# apollo4b register map
Vendor: Ambiq Micro; Series: Apollo; File version: 1.0
CPU: CM4 r1p0, little endian, MPU, FPU, I-cache, D-cache, VTOR, ITCM, DTCM, 3 interrupt priority bits, 0 interrupts
Registers are 32-bit, read-write, reset 0x0 unless marked. A register's access mark holds for its fields unless they carry their own. Offsets are from the block's base; [hi:lo] are bit positions; {n}, {i} and the like mark numbered series; 'fields as' and 'values as' point back to an identical list.

## GPIO (part 3 of 4) — General Purpose IO
Base 0x40010000
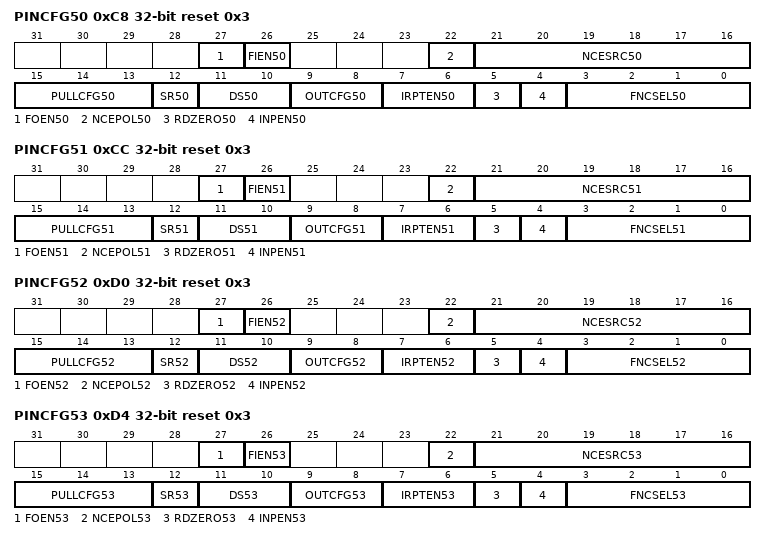
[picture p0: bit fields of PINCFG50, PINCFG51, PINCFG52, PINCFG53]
0xC8 PINCFG50 reset 0x3 — Controls the operation of GPIO pin 50.
  [27] FOEN50 — Force output enable active regardless of function selected. Otherwise the selected function will enable the output only when needed
  [26] FIEN50 — Force input enable active regardless of function selected. Otherwise the selected function will enable the input only when needed
  [22] NCEPOL50 — Polarity select for NCE for GPIO 50
    0=LOW (Polarity is active low); 1=HIGH (Polarity is active high)
  [21:16] NCESRC50 — IOMSTR/MSPI N Chip Select 50, DISP control signals DE, CSX, and CS. Polarity is determined by CE_POLARITY field
    {v}=IOM0CE{v} (IOM 0 NCE {v} module) (v=0..3); {v}=IOM1CE{v-4} (IOM 1 NCE {v-4} module) (v=4..7); {v}=IOM2CE{v-8} (IOM 2 NCE {v-8} module) (v=8..11); {v}=IOM3CE{v-12} (IOM 3 NCE {v-12} module) (v=12..15); {v}=IOM4CE{v-16} (IOM 4 NCE {v-16} module) (v=16..19); {v}=IOM5CE{v-20} (IOM 5 NCE {v-20} module) (v=20..23); {v}=IOM6CE{v-24} (IOM 6 NCE {v-24} module) (v=24..27); {v}=IOM7CE{v-28} (IOM 7 NCE {v-28} module) (v=28..31); 32=MSPI0CEN0 (MSPI 0 NCE 0 module); 33=MSPI0CEN1 (MSPI 0 NCE 1 module); 34=MSPI1CEN0 (MSPI 1 NCE 0 module); 35=MSPI1CEN1 (MSPI 1 NCE 1 module); 36=MSPI2CEN0 (MSPI 2 NCE 0 module); 37=MSPI2CEN1 (MSPI 2 NCE 1 module); 38=DC_DPI_DE (DC DPI DE module); 39=DISP_CONT_CSX (DISP CONT CSX module); 40=DC_SPI_CS_N (DC SPI CS_N module); 41=DC_QSPI_CS_N (DC QSPI CS_N module); 42=DC_RESX (DC module RESX)
  [15:13] PULLCFG50 — Pullup/Pulldown configuration for GPIO 50
    0=DIS (No pullup or pulldown selected); 1=PD50K (50K Pulldown selected); 2=PU15K (1.5K Pullup selected); 3=PU6K (6K Pullup selected); 4=PU12K (12K Pullup selected); 5=PU24K (24K Pullup selected); 6=PU50K (50K Pullup selected); 7=PU100K (100K Pullup selected)
  [12] SR50 — Configure the slew rate
  [11:10] DS50 — Drive strength selection for GPIO 50
    0=0P1X (0.1x output driver selected); 1=0P5X (0.5x output driver selected)
  [9:8] OUTCFG50 — Pin IO mode selection for GPIO pin 50
    0=DIS (Output Disabled); 1=PUSHPULL (Output configured in push pull mode. Will drive 0 and 1 values on pin.); 2=OD (Output configured in open drain mode. Will only drive pin low, tristate otherwise.); 3=TS (Output configured in Tristate-able push pull mode. Will drive 0, 1 of HiZ on pin.)
  [7:6] IRPTEN50 — Interrupt enable for GPIO 50
    0=DIS (Interrupts are disabled for this GPIO); 1=INTFALL (Interrupts are enabled for falling edge transition on this GPIO); 2=INTRISE (Interrupts are enabled for rising edge transitions on this GPIO); 3=INTANY (Interrupts are enabled for any edge transition on this GPIO)
  [5] RDZERO50 — Return 0 for read data on GPIO 50
  [4] INPEN50 — Input enable for GPIO 50
  [3:0] FNCSEL50 — Function select for GPIO pin 50
    0=PDM0_CLK (PDMx Clock output (I2C Master/Slave D)); 1=TRIG0 (ADC trigger input); 2=SWTRACECLK (Serial Wire Debug Trace Clock); 3=GPIO (General purpose I/O); 4=UART2RTS (UART Request to Send (RTS) (UART 2)); 5=UART3RTS (UART Request to Send (RTS) (UART 3)); 6=CT50 (Timer/Counter input or output; Selection of direction is done via CTIMER register settings.); 7=NCE50 (IOMSTR/MSPI N Chip Select. Polarity is determined by CE_POLARITY field); 8=OBSBUS2 (Observation bus bit 2); 9=DISP_TE (Display TE input); 11=FPIO (Fast PIO)
0xCC PINCFG51 reset 0x3 — Controls the operation of GPIO pin 51.
  [27] FOEN51 — Force output enable active regardless of function selected. Otherwise the selected function will enable the output only when needed
  [26] FIEN51 — Force input enable active regardless of function selected. Otherwise the selected function will enable the input only when needed
  [22] NCEPOL51 — Polarity select for NCE for GPIO 51
    values as PINCFG50.NCEPOL50
  [21:16] NCESRC51 — IOMSTR/MSPI N Chip Select 51, DISP control signals DE, CSX, and CS. Polarity is determined by CE_POLARITY field
    values as PINCFG50.NCESRC50
  [15:13] PULLCFG51 — Pullup/Pulldown configuration for GPIO 51
    values as PINCFG50.PULLCFG50
  [12] SR51 — Configure the slew rate
  [11:10] DS51 — Drive strength selection for GPIO 51
    0=0P1X (0.1x output driver selected); 1=0P5X (0.5x output driver selected); 2=0P75X (0.75x output driver selected); 3=1P0X (1.0x output driver selected)
  [9:8] OUTCFG51 — Pin IO mode selection for GPIO pin 51
    values as PINCFG50.OUTCFG50
  [7:6] IRPTEN51 — Interrupt enable for GPIO 51
    values as PINCFG50.IRPTEN50
  [5] RDZERO51 — Return 0 for read data on GPIO 51
  [4] INPEN51 — Input enable for GPIO 51
  [3:0] FNCSEL51 — Function select for GPIO pin 51
    0=PDM0_DATA (PDMx audio data input to chip (I2C Master/Slave D)); 1=TRIG1 (ADC trigger input); 2=SWTRACE0 (Serial Wire Debug Trace Output 0); 3=GPIO (General purpose I/O); 4=UART0CTS (UART Clear to Send (CTS) (UART 0)); 5=UART1CTS (UART Clear to Send (CTS) (UART 1)); 6=CT51 (Timer/Counter input or output; Selection of direction is done via CTIMER register settings.); 7=NCE51 (IOMSTR/MSPI N Chip Select. Polarity is determined by CE_POLARITY field); 8=OBSBUS3 (Observation bus bit 3); 11=FPIO (Fast PIO)
0xD0 PINCFG52 reset 0x3 — Controls the operation of GPIO pin 52.
  [27] FOEN52 — Force output enable active regardless of function selected. Otherwise the selected function will enable the output only when needed
  [26] FIEN52 — Force input enable active regardless of function selected. Otherwise the selected function will enable the input only when needed
  [22] NCEPOL52 — Polarity select for NCE for GPIO 52
    values as PINCFG50.NCEPOL50
  [21:16] NCESRC52 — IOMSTR/MSPI N Chip Select 52, DISP control signals DE, CSX, and CS. Polarity is determined by CE_POLARITY field
    values as PINCFG50.NCESRC50
  [15:13] PULLCFG52 — Pullup/Pulldown configuration for GPIO 52
    values as PINCFG50.PULLCFG50
  [12] SR52 — Configure the slew rate
  [11:10] DS52 — Drive strength selection for GPIO 52
    values as PINCFG51.DS51
  [9:8] OUTCFG52 — Pin IO mode selection for GPIO pin 52
    values as PINCFG50.OUTCFG50
  [7:6] IRPTEN52 — Interrupt enable for GPIO 52
    values as PINCFG50.IRPTEN50
  [5] RDZERO52 — Return 0 for read data on GPIO 52
  [4] INPEN52 — Input enable for GPIO 52
  [3:0] FNCSEL52 — Function select for GPIO pin 52
    0=PDM1_CLK (PDMx Clock output (I2C Master/Slave D)); 1=TRIG2 (ADC trigger input); 2=SWTRACE1 (Serial Wire Debug Trace Output 1); 3=GPIO (General purpose I/O); 4=UART2CTS (UART Clear to Send (CTS) (UART 2)); 5=UART3CTS (UART Clear to Send (CTS) (UART 3)); 6=CT52 (Timer/Counter input or output; Selection of direction is done via CTIMER register settings.); 7=NCE52 (IOMSTR/MSPI N Chip Select. Polarity is determined by CE_POLARITY field); 8=OBSBUS4 (Observation bus bit 4); 9=VCMPO (Output of the voltage comparator signal); 11=FPIO (Fast PIO)
0xD4 PINCFG53 reset 0x3 — Controls the operation of GPIO pin 53.
  [27] FOEN53 — Force output enable active regardless of function selected. Otherwise the selected function will enable the output only when needed
  [26] FIEN53 — Force input enable active regardless of function selected. Otherwise the selected function will enable the input only when needed
  [22] NCEPOL53 — Polarity select for NCE for GPIO 53
    values as PINCFG50.NCEPOL50
  [21:16] NCESRC53 — IOMSTR/MSPI N Chip Select 53, DISP control signals DE, CSX, and CS. Polarity is determined by CE_POLARITY field
    values as PINCFG50.NCESRC50
  [15:13] PULLCFG53 — Pullup/Pulldown configuration for GPIO 53
    values as PINCFG50.PULLCFG50
  [12] SR53 — Configure the slew rate
  [11:10] DS53 — Drive strength selection for GPIO 53
    values as PINCFG51.DS51
  [9:8] OUTCFG53 — Pin IO mode selection for GPIO pin 53
    values as PINCFG50.OUTCFG50
  [7:6] IRPTEN53 — Interrupt enable for GPIO 53
    values as PINCFG50.IRPTEN50
  [5] RDZERO53 — Return 0 for read data on GPIO 53
  [4] INPEN53 — Input enable for GPIO 53
  [3:0] FNCSEL53 — Function select for GPIO pin 53
    0=PDM1_DATA (PDMx audio data input to chip (I2C Master/Slave D)); 1=TRIG3 (ADC trigger input); 2=SWTRACE2 (Serial Wire Debug Trace Output 2); 3=GPIO (General purpose I/O); 4=UART0TX (UART transmit output (UART 0)); 5=UART1TX (UART transmit output (UART 1)); 6=CT53 (Timer/Counter input or output; Selection of direction is done via CTIMER register settings.); 7=NCE53 (IOMSTR/MSPI N Chip Select. Polarity is determined by CE_POLARITY field); 8=OBSBUS5 (Observation bus bit 5); 11=FPIO (Fast PIO)
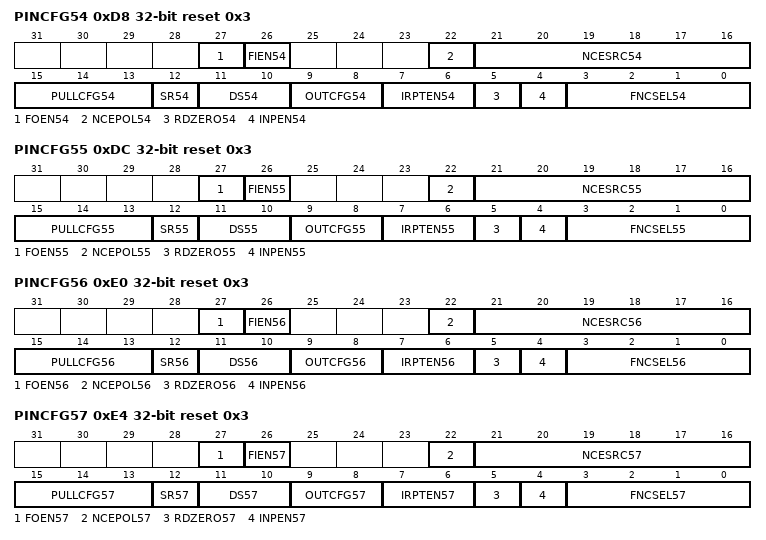
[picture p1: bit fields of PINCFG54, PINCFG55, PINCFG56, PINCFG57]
0xD8 PINCFG54 reset 0x3 — Controls the operation of GPIO pin 54.
  [27] FOEN54 — Force output enable active regardless of function selected. Otherwise the selected function will enable the output only when needed
  [26] FIEN54 — Force input enable active regardless of function selected. Otherwise the selected function will enable the input only when needed
  [22] NCEPOL54 — Polarity select for NCE for GPIO 54
    values as PINCFG50.NCEPOL50
  [21:16] NCESRC54 — IOMSTR/MSPI N Chip Select 54, DISP control signals DE, CSX, and CS. Polarity is determined by CE_POLARITY field
    values as PINCFG50.NCESRC50
  [15:13] PULLCFG54 — Pullup/Pulldown configuration for GPIO 54
    values as PINCFG50.PULLCFG50
  [12] SR54 — Configure the slew rate
  [11:10] DS54 — Drive strength selection for GPIO 54
    values as PINCFG51.DS51
  [9:8] OUTCFG54 — Pin IO mode selection for GPIO pin 54
    values as PINCFG50.OUTCFG50
  [7:6] IRPTEN54 — Interrupt enable for GPIO 54
    values as PINCFG50.IRPTEN50
  [5] RDZERO54 — Return 0 for read data on GPIO 54
  [4] INPEN54 — Input enable for GPIO 54
  [3:0] FNCSEL54 — Function select for GPIO pin 54
    0=PDM2_CLK (PDMx Clock output (I2C Master/Slave D)); 1=TRIG0 (ADC trigger input); 2=SWTRACE3 (Serial Wire Debug Trace Output 3); 3=GPIO (General purpose I/O); 4=UART2TX (UART transmit output (UART 2)); 5=UART3TX (UART transmit output (UART 3)); 6=CT54 (Timer/Counter input or output; Selection of direction is done via CTIMER register settings.); 7=NCE54 (IOMSTR/MSPI N Chip Select. Polarity is determined by CE_POLARITY field); 8=OBSBUS6 (Observation bus bit 6); 11=FPIO (Fast PIO)
0xDC PINCFG55 reset 0x3 — Controls the operation of GPIO pin 55.
  [27] FOEN55 — Force output enable active regardless of function selected. Otherwise the selected function will enable the output only when needed
  [26] FIEN55 — Force input enable active regardless of function selected. Otherwise the selected function will enable the input only when needed
  [22] NCEPOL55 — Polarity select for NCE for GPIO 55
    values as PINCFG50.NCEPOL50
  [21:16] NCESRC55 — IOMSTR/MSPI N Chip Select 55, DISP control signals DE, CSX, and CS. Polarity is determined by CE_POLARITY field
    values as PINCFG50.NCESRC50
  [15:13] PULLCFG55 — Pullup/Pulldown configuration for GPIO 55
    values as PINCFG50.PULLCFG50
  [12] SR55 — Configure the slew rate
  [11:10] DS55 — Drive strength selection for GPIO 55
    values as PINCFG51.DS51
  [9:8] OUTCFG55 — Pin IO mode selection for GPIO pin 55
    values as PINCFG50.OUTCFG50
  [7:6] IRPTEN55 — Interrupt enable for GPIO 55
    values as PINCFG50.IRPTEN50
  [5] RDZERO55 — Return 0 for read data on GPIO 55
  [4] INPEN55 — Input enable for GPIO 55
  [3:0] FNCSEL55 — Function select for GPIO pin 55
    0=PDM2_DATA (PDMx audio data input to chip (I2C Master/Slave D)); 1=TRIG1 (ADC trigger input); 2=SWTRACECTL (Serial Wire Debug Trace Control); 3=GPIO (General purpose I/O); 4=UART0RX (UART receive input (UART 0)); 5=UART1RX (UART receive input (UART 1)); 6=CT55 (Timer/Counter input or output; Selection of direction is done via CTIMER register settings.); 7=NCE55 (IOMSTR/MSPI N Chip Select. Polarity is determined by CE_POLARITY field); 8=OBSBUS7 (Observation bus bit 7); 11=FPIO (Fast PIO)
0xE0 PINCFG56 reset 0x3 — Controls the operation of GPIO pin 56.
  [27] FOEN56 — Force output enable active regardless of function selected. Otherwise the selected function will enable the output only when needed
  [26] FIEN56 — Force input enable active regardless of function selected. Otherwise the selected function will enable the input only when needed
  [22] NCEPOL56 — Polarity select for NCE for GPIO 56
    values as PINCFG50.NCEPOL50
  [21:16] NCESRC56 — IOMSTR/MSPI N Chip Select 56, DISP control signals DE, CSX, and CS. Polarity is determined by CE_POLARITY field
    values as PINCFG50.NCESRC50
  [15:13] PULLCFG56 — Pullup/Pulldown configuration for GPIO 56
    values as PINCFG50.PULLCFG50
  [12] SR56 — Configure the slew rate
  [11:10] DS56 — Drive strength selection for GPIO 56
    values as PINCFG51.DS51
  [9:8] OUTCFG56 — Pin IO mode selection for GPIO pin 56
    values as PINCFG50.OUTCFG50
  [7:6] IRPTEN56 — Interrupt enable for GPIO 56
    values as PINCFG50.IRPTEN50
  [5] RDZERO56 — Return 0 for read data on GPIO 56
  [4] INPEN56 — Input enable for GPIO 56
  [3:0] FNCSEL56 — Function select for GPIO pin 56
    0=PDM3_CLK (PDMx Clock output (I2C Master/Slave D)); 1=TRIG2 (ADC trigger input); 2=SWO (Serial Wire Output); 3=GPIO (General purpose I/O); 4=UART2RX (UART receive input (UART 2)); 5=UART3RX (UART receive input (UART 3)); 6=CT56 (Timer/Counter input or output; Selection of direction is done via CTIMER register settings.); 7=NCE56 (IOMSTR/MSPI N Chip Select. Polarity is determined by CE_POLARITY field); 8=OBSBUS8 (Observation bus bit 8); 11=FPIO (Fast PIO)
0xE4 PINCFG57 reset 0x3 — Controls the operation of GPIO pin 57.
  [27] FOEN57 — Force output enable active regardless of function selected. Otherwise the selected function will enable the output only when needed
  [26] FIEN57 — Force input enable active regardless of function selected. Otherwise the selected function will enable the input only when needed
  [22] NCEPOL57 — Polarity select for NCE for GPIO 57
    values as PINCFG50.NCEPOL50
  [21:16] NCESRC57 — IOMSTR/MSPI N Chip Select 57, DISP control signals DE, CSX, and CS. Polarity is determined by CE_POLARITY field
    values as PINCFG50.NCESRC50
  [15:13] PULLCFG57 — Pullup/Pulldown configuration for GPIO 57
    values as PINCFG50.PULLCFG50
  [12] SR57 — Configure the slew rate
  [11:10] DS57 — Drive strength selection for GPIO 57
    values as PINCFG51.DS51
  [9:8] OUTCFG57 — Pin IO mode selection for GPIO pin 57
    values as PINCFG50.OUTCFG50
  [7:6] IRPTEN57 — Interrupt enable for GPIO 57
    values as PINCFG50.IRPTEN50
  [5] RDZERO57 — Return 0 for read data on GPIO 57
  [4] INPEN57 — Input enable for GPIO 57
  [3:0] FNCSEL57 — Function select for GPIO pin 57
    0=PDM3_DATA (PDMx audio data input to chip (I2C Master/Slave D)); 1=TRIG3 (ADC trigger input); 2=SWO (Serial Wire Output); 3=GPIO (General purpose I/O); 4=UART0RTS (UART Request to Send (RTS) (UART 0)); 5=UART1RTS (UART Request to Send (RTS) (UART 1)); 6=CT57 (Timer/Counter input or output; Selection of direction is done via CTIMER register settings.); 7=NCE57 (IOMSTR/MSPI N Chip Select. Polarity is determined by CE_POLARITY field); 8=OBSBUS9 (Observation bus bit 9); 9=VCMPO (Output of the voltage comparator signal); 11=FPIO (Fast PIO)
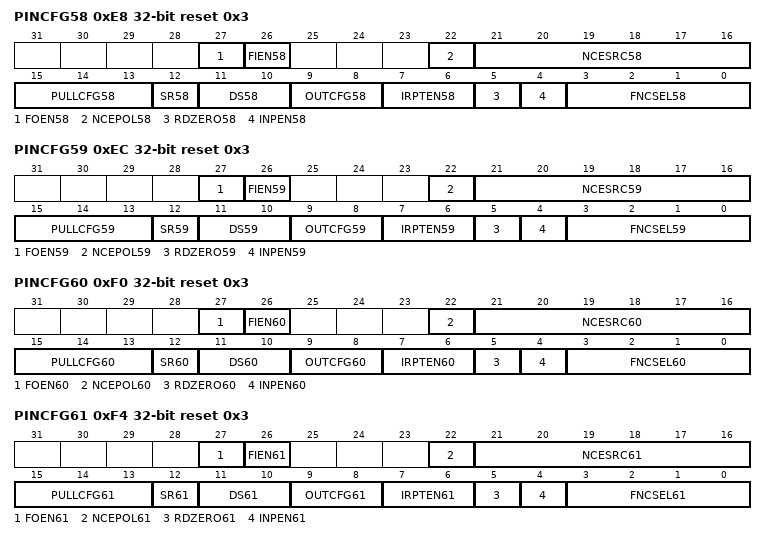
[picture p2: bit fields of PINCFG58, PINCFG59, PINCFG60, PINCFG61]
0xE8 PINCFG58 reset 0x3 — Controls the operation of GPIO pin 58.
  [27] FOEN58 — Force output enable active regardless of function selected. Otherwise the selected function will enable the output only when needed
  [26] FIEN58 — Force input enable active regardless of function selected. Otherwise the selected function will enable the input only when needed
  [22] NCEPOL58 — Polarity select for NCE for GPIO 58
    values as PINCFG50.NCEPOL50
  [21:16] NCESRC58 — IOMSTR/MSPI N Chip Select 58, DISP control signals DE, CSX, and CS. Polarity is determined by CE_POLARITY field
    values as PINCFG50.NCESRC50
  [15:13] PULLCFG58 — Pullup/Pulldown configuration for GPIO 58
    values as PINCFG50.PULLCFG50
  [12] SR58 — Configure the slew rate
  [11:10] DS58 — Drive strength selection for GPIO 58
    values as PINCFG50.DS50
  [9:8] OUTCFG58 — Pin IO mode selection for GPIO pin 58
    values as PINCFG50.OUTCFG50
  [7:6] IRPTEN58 — Interrupt enable for GPIO 58
    values as PINCFG50.IRPTEN50
  [5] RDZERO58 — Return 0 for read data on GPIO 58
  [4] INPEN58 — Input enable for GPIO 58
  [3:0] FNCSEL58 — Function select for GPIO pin 58
    3=GPIO (General purpose I/O); 4=UART0RTS (UART Request to Send (RTS) (UART 0)); 5=UART3RTS (UART Request to Send (RTS) (UART 3)); 6=CT58 (Timer/Counter input or output; Selection of direction is done via CTIMER register settings.); 7=NCE58 (IOMSTR/MSPI N Chip Select. Polarity is determined by CE_POLARITY field); 8=OBSBUS10 (Observation bus bit 10); 11=FPIO (Fast PIO)
0xEC PINCFG59 reset 0x3 — Controls the operation of GPIO pin 59.
  [27] FOEN59 — Force output enable active regardless of function selected. Otherwise the selected function will enable the output only when needed
  [26] FIEN59 — Force input enable active regardless of function selected. Otherwise the selected function will enable the input only when needed
  [22] NCEPOL59 — Polarity select for NCE for GPIO 59
    values as PINCFG50.NCEPOL50
  [21:16] NCESRC59 — IOMSTR/MSPI N Chip Select 59, DISP control signals DE, CSX, and CS. Polarity is determined by CE_POLARITY field
    values as PINCFG50.NCESRC50
  [15:13] PULLCFG59 — Pullup/Pulldown configuration for GPIO 59
    values as PINCFG50.PULLCFG50
  [12] SR59 — Configure the slew rate
  [11:10] DS59 — Drive strength selection for GPIO 59
    values as PINCFG50.DS50
  [9:8] OUTCFG59 — Pin IO mode selection for GPIO pin 59
    values as PINCFG50.OUTCFG50
  [7:6] IRPTEN59 — Interrupt enable for GPIO 59
    values as PINCFG50.IRPTEN50
  [5] RDZERO59 — Return 0 for read data on GPIO 59
  [4] INPEN59 — Input enable for GPIO 59
  [3:0] FNCSEL59 — Function select for GPIO pin 59
    1=TRIG0 (ADC trigger input); 3=GPIO (General purpose I/O); 4=UART0CTS (UART Clear to Send (CTS) (UART 0)); 5=UART1CTS (UART Clear to Send (CTS) (UART 1)); 6=CT59 (Timer/Counter input or output; Selection of direction is done via CTIMER register settings.); 7=NCE59 (IOMSTR/MSPI N Chip Select. Polarity is determined by CE_POLARITY field); 8=OBSBUS11 (Observation bus bit 11); 11=FPIO (Fast PIO)
0xF0 PINCFG60 reset 0x3 — Controls the operation of GPIO pin 60.
  [27] FOEN60 — Force output enable active regardless of function selected. Otherwise the selected function will enable the output only when needed
  [26] FIEN60 — Force input enable active regardless of function selected. Otherwise the selected function will enable the input only when needed
  [22] NCEPOL60 — Polarity select for NCE for GPIO 60
    values as PINCFG50.NCEPOL50
  [21:16] NCESRC60 — IOMSTR/MSPI N Chip Select 60, DISP control signals DE, CSX, and CS. Polarity is determined by CE_POLARITY field
    values as PINCFG50.NCESRC50
  [15:13] PULLCFG60 — Pullup/Pulldown configuration for GPIO 60
    values as PINCFG50.PULLCFG50
  [12] SR60 — Configure the slew rate
  [11:10] DS60 — Drive strength selection for GPIO 60
    values as PINCFG50.DS50
  [9:8] OUTCFG60 — Pin IO mode selection for GPIO pin 60
    values as PINCFG50.OUTCFG50
  [7:6] IRPTEN60 — Interrupt enable for GPIO 60
    values as PINCFG50.IRPTEN50
  [5] RDZERO60 — Return 0 for read data on GPIO 60
  [4] INPEN60 — Input enable for GPIO 60
  [3:0] FNCSEL60 — Function select for GPIO pin 60
    1=TRIG1 (ADC trigger input); 3=GPIO (General purpose I/O); 4=UART0TX (UART transmit output (UART 0)); 5=UART3CTS (UART Clear to Send (CTS) (UART 3)); 6=CT60 (Timer/Counter input or output; Selection of direction is done via CTIMER register settings.); 7=NCE60 (IOMSTR/MSPI N Chip Select. Polarity is determined by CE_POLARITY field); 8=OBSBUS12 (Observation bus bit 12); 11=FPIO (Fast PIO)
0xF4 PINCFG61 reset 0x3 — Controls the operation of GPIO pin 61.
  [27] FOEN61 — Force output enable active regardless of function selected. Otherwise the selected function will enable the output only when needed
  [26] FIEN61 — Force input enable active regardless of function selected. Otherwise the selected function will enable the input only when needed
  [22] NCEPOL61 — Polarity select for NCE for GPIO 61
    values as PINCFG50.NCEPOL50
  [21:16] NCESRC61 — IOMSTR/MSPI N Chip Select 61, DISP control signals DE, CSX, and CS. Polarity is determined by CE_POLARITY field
    values as PINCFG50.NCESRC50
  [15:13] PULLCFG61 — Pullup/Pulldown configuration for GPIO 61
    values as PINCFG50.PULLCFG50
  [12] SR61 — Configure the slew rate
  [11:10] DS61 — Drive strength selection for GPIO 61
    values as PINCFG51.DS51
  [9:8] OUTCFG61 — Pin IO mode selection for GPIO pin 61
    values as PINCFG50.OUTCFG50
  [7:6] IRPTEN61 — Interrupt enable for GPIO 61
    values as PINCFG50.IRPTEN50
  [5] RDZERO61 — Return 0 for read data on GPIO 61
  [4] INPEN61 — Input enable for GPIO 61
  [3:0] FNCSEL61 — Function select for GPIO pin 61
    0=M6SCL (Serial I2C Master Clock output (IOM 6)); 1=M6SCK (Serial SPI Master Clock output (IOM 6)); 2=I2S1_CLK (Bidirectional I2S Bit clock. Operates in output mode in master mode and input mode for slave mode. (I2S Master/Slave 2)); 3=GPIO (General purpose I/O); 4=UART2TX (UART transmit output (UART 2)); 5=UART3TX (UART transmit output (UART 3)); 6=CT61 (Timer/Counter input or output; Selection of direction is done via CTIMER register settings.); 7=NCE61 (IOMSTR/MSPI N Chip Select. Polarity is determined by CE_POLARITY field); 8=OBSBUS13 (Observation bus bit 13); 11=FPIO (Fast PIO)
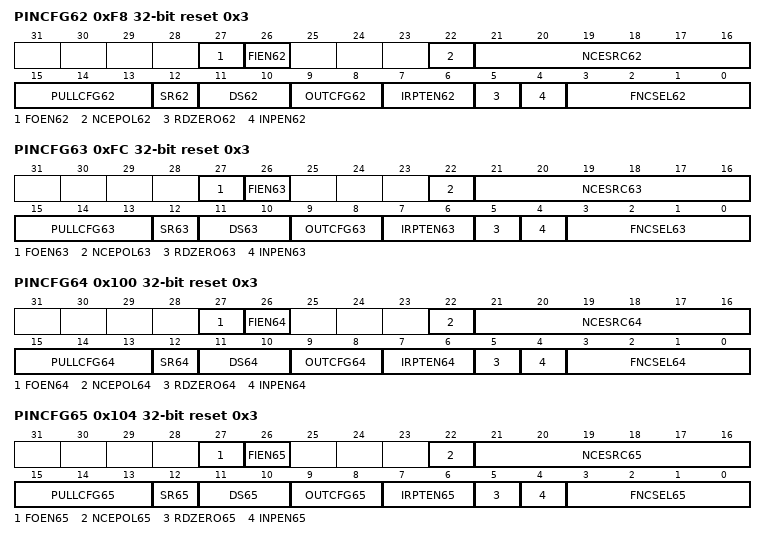
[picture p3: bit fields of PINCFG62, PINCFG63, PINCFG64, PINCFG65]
0xF8 PINCFG62 reset 0x3 — Controls the operation of GPIO pin 62.
  [27] FOEN62 — Force output enable active regardless of function selected. Otherwise the selected function will enable the output only when needed
  [26] FIEN62 — Force input enable active regardless of function selected. Otherwise the selected function will enable the input only when needed
  [22] NCEPOL62 — Polarity select for NCE for GPIO 62
    values as PINCFG50.NCEPOL50
  [21:16] NCESRC62 — IOMSTR/MSPI N Chip Select 62, DISP control signals DE, CSX, and CS. Polarity is determined by CE_POLARITY field
    values as PINCFG50.NCESRC50
  [15:13] PULLCFG62 — Pullup/Pulldown configuration for GPIO 62
    values as PINCFG50.PULLCFG50
  [12] SR62 — Configure the slew rate
  [11:10] DS62 — Drive strength selection for GPIO 62
    values as PINCFG51.DS51
  [9:8] OUTCFG62 — Pin IO mode selection for GPIO pin 62
    values as PINCFG50.OUTCFG50
  [7:6] IRPTEN62 — Interrupt enable for GPIO 62
    values as PINCFG50.IRPTEN50
  [5] RDZERO62 — Return 0 for read data on GPIO 62
  [4] INPEN62 — Input enable for GPIO 62
  [3:0] FNCSEL62 — Function select for GPIO pin 62
    0=M6SDAWIR3 (Serial I2C Master Data I/O (I2C Mode) Serial SPI Master Data I/O (SPI 3 wire mode) (IOM 6)); 1=M6MOSI (Serial SPI Master MOSI output (IOM 6)); 2=I2S1_DATA (Bidirectional I2S Data. Operates in output mode in master mode and input mode for slave mode. (I2S Master/Slave 2)); 3=GPIO (General purpose I/O); 4=UART0RX (UART receive input (UART 0)); 5=UART1RX (UART receive input (UART 1)); 6=CT62 (Timer/Counter input or output; Selection of direction is done via CTIMER register settings.); 7=NCE62 (IOMSTR/MSPI N Chip Select. Polarity is determined by CE_POLARITY field); 8=OBSBUS14 (Observation bus bit 14); 9=I2S1_SDOUT (I2S Data output (I2S Master/Slave 2)); 11=FPIO (Fast PIO)
0xFC PINCFG63 reset 0x3 — Controls the operation of GPIO pin 63.
  [27] FOEN63 — Force output enable active regardless of function selected. Otherwise the selected function will enable the output only when needed
  [26] FIEN63 — Force input enable active regardless of function selected. Otherwise the selected function will enable the input only when needed
  [22] NCEPOL63 — Polarity select for NCE for GPIO 63
    values as PINCFG50.NCEPOL50
  [21:16] NCESRC63 — IOMSTR/MSPI N Chip Select 63, DISP control signals DE, CSX, and CS. Polarity is determined by CE_POLARITY field
    values as PINCFG50.NCESRC50
  [15:13] PULLCFG63 — Pullup/Pulldown configuration for GPIO 63
    values as PINCFG50.PULLCFG50
  [12] SR63 — Configure the slew rate
  [11:10] DS63 — Drive strength selection for GPIO 63
    values as PINCFG51.DS51
  [9:8] OUTCFG63 — Pin IO mode selection for GPIO pin 63
    values as PINCFG50.OUTCFG50
  [7:6] IRPTEN63 — Interrupt enable for GPIO 63
    values as PINCFG50.IRPTEN50
  [5] RDZERO63 — Return 0 for read data on GPIO 63
  [4] INPEN63 — Input enable for GPIO 63
  [3:0] FNCSEL63 — Function select for GPIO pin 63
    0=M6MISO (Serial SPI MASTER MISO input (IOM 6)); 1=CLKOUT (Oscillator output clock); 2=I2S1_WS (Bidirectional I2S L/R clock. Operates in output mode in master mode and input mode for slave mode. (I2S Master/Slave 2)); 3=GPIO (General purpose I/O); 4=UART2RX (UART receive input (UART 2)); 5=UART3RX (UART receive input (UART 3)); 6=CT63 (Timer/Counter input or output; Selection of direction is done via CTIMER register settings.); 7=NCE63 (IOMSTR/MSPI N Chip Select. Polarity is determined by CE_POLARITY field); 8=OBSBUS15 (Observation bus bit 15); 9=DISP_TE (Display TE input); 11=FPIO (Fast PIO)
0x100 PINCFG64 reset 0x3 — Controls the operation of GPIO pin 64.
  [27] FOEN64 — Force output enable active regardless of function selected. Otherwise the selected function will enable the output only when needed
  [26] FIEN64 — Force input enable active regardless of function selected. Otherwise the selected function will enable the input only when needed
  [22] NCEPOL64 — Polarity select for NCE for GPIO 64
    values as PINCFG50.NCEPOL50
  [21:16] NCESRC64 — IOMSTR/MSPI N Chip Select 64, DISP control signals DE, CSX, and CS. Polarity is determined by CE_POLARITY field
    values as PINCFG50.NCESRC50
  [15:13] PULLCFG64 — Pullup/Pulldown configuration for GPIO 64
    values as PINCFG50.PULLCFG50
  [12] SR64 — Configure the slew rate
  [11:10] DS64 — Drive strength selection for GPIO 64
    values as PINCFG51.DS51
  [9:8] OUTCFG64 — Pin IO mode selection for GPIO pin 64
    values as PINCFG50.OUTCFG50
  [7:6] IRPTEN64 — Interrupt enable for GPIO 64
    values as PINCFG50.IRPTEN50
  [5] RDZERO64 — Return 0 for read data on GPIO 64
  [4] INPEN64 — Input enable for GPIO 64
  [3:0] FNCSEL64 — Function select for GPIO pin 64
    0=MSPI0_0 (MSPI Master 0 Interface Signal); 1=32KHzXT (32kHZ from analog); 2=SWO (Serial Wire Output); 3=GPIO (General purpose I/O); 4=UART0RTS (UART Request to Send (RTS) (UART 0)); 5=DISP_D0 (Display Data 0); 6=CT64 (Timer/Counter input or output; Selection of direction is done via CTIMER register settings.); 7=NCE64 (IOMSTR/MSPI N Chip Select. Polarity is determined by CE_POLARITY field); 8=OBSBUS0 (Observation bus bit 0); 9=I2S1_SDIN (I2S Data input (I2S Master/Slave 2)); 11=FPIO (Fast PIO)
0x104 PINCFG65 reset 0x3 — Controls the operation of GPIO pin 65.
  [27] FOEN65 — Force output enable active regardless of function selected. Otherwise the selected function will enable the output only when needed
  [26] FIEN65 — Force input enable active regardless of function selected. Otherwise the selected function will enable the input only when needed
  [22] NCEPOL65 — Polarity select for NCE for GPIO 65
    values as PINCFG50.NCEPOL50
  [21:16] NCESRC65 — IOMSTR/MSPI N Chip Select 65, DISP control signals DE, CSX, and CS. Polarity is determined by CE_POLARITY field
    values as PINCFG50.NCESRC50
  [15:13] PULLCFG65 — Pullup/Pulldown configuration for GPIO 65
    values as PINCFG50.PULLCFG50
  [12] SR65 — Configure the slew rate
  [11:10] DS65 — Drive strength selection for GPIO 65
    values as PINCFG51.DS51
  [9:8] OUTCFG65 — Pin IO mode selection for GPIO pin 65
    values as PINCFG50.OUTCFG50
  [7:6] IRPTEN65 — Interrupt enable for GPIO 65
    values as PINCFG50.IRPTEN50
  [5] RDZERO65 — Return 0 for read data on GPIO 65
  [4] INPEN65 — Input enable for GPIO 65
  [3:0] FNCSEL65 — Function select for GPIO pin 65
    0=MSPI0_1 (MSPI Master 0 Interface Signal); 1=32KHzXT (32kHZ from analog); 2=SWO (Serial Wire Output); 3=GPIO (General purpose I/O); 4=UART0CTS (UART Clear to Send (CTS) (UART 0)); 5=DISP_D1 (Display Data 1); 6=CT65 (Timer/Counter input or output; Selection of direction is done via CTIMER register settings.); 7=NCE65 (IOMSTR/MSPI N Chip Select. Polarity is determined by CE_POLARITY field); 8=OBSBUS1 (Observation bus bit 1); 11=FPIO (Fast PIO)
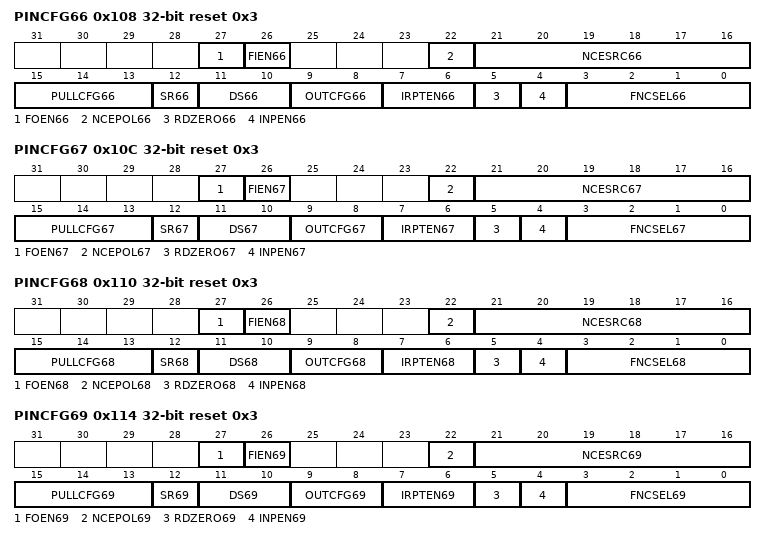
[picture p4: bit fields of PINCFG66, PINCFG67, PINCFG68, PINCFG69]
0x108 PINCFG66 reset 0x3 — Controls the operation of GPIO pin 66.
  [27] FOEN66 — Force output enable active regardless of function selected. Otherwise the selected function will enable the output only when needed
  [26] FIEN66 — Force input enable active regardless of function selected. Otherwise the selected function will enable the input only when needed
  [22] NCEPOL66 — Polarity select for NCE for GPIO 66
    values as PINCFG50.NCEPOL50
  [21:16] NCESRC66 — IOMSTR/MSPI N Chip Select 66, DISP control signals DE, CSX, and CS. Polarity is determined by CE_POLARITY field
    values as PINCFG50.NCESRC50
  [15:13] PULLCFG66 — Pullup/Pulldown configuration for GPIO 66
    values as PINCFG50.PULLCFG50
  [12] SR66 — Configure the slew rate
  [11:10] DS66 — Drive strength selection for GPIO 66
    values as PINCFG51.DS51
  [9:8] OUTCFG66 — Pin IO mode selection for GPIO pin 66
    values as PINCFG50.OUTCFG50
  [7:6] IRPTEN66 — Interrupt enable for GPIO 66
    values as PINCFG50.IRPTEN50
  [5] RDZERO66 — Return 0 for read data on GPIO 66
  [4] INPEN66 — Input enable for GPIO 66
  [3:0] FNCSEL66 — Function select for GPIO pin 66
    0=MSPI0_2 (MSPI Master 0 Interface Signal); 1=CLKOUT (Oscillator output clock); 2=SWO (Serial Wire Output); 3=GPIO (General purpose I/O); 4=UART0TX (UART transmit output (UART 0)); 5=DISP_D2 (Display Data 2); 6=CT66 (Timer/Counter input or output; Selection of direction is done via CTIMER register settings.); 7=NCE66 (IOMSTR/MSPI N Chip Select. Polarity is determined by CE_POLARITY field); 8=OBSBUS2 (Observation bus bit 2); 11=FPIO (Fast PIO)
0x10C PINCFG67 reset 0x3 — Controls the operation of GPIO pin 67.
  [27] FOEN67 — Force output enable active regardless of function selected. Otherwise the selected function will enable the output only when needed
  [26] FIEN67 — Force input enable active regardless of function selected. Otherwise the selected function will enable the input only when needed
  [22] NCEPOL67 — Polarity select for NCE for GPIO 67
    values as PINCFG50.NCEPOL50
  [21:16] NCESRC67 — IOMSTR/MSPI N Chip Select 67, DISP control signals DE, CSX, and CS. Polarity is determined by CE_POLARITY field
    values as PINCFG50.NCESRC50
  [15:13] PULLCFG67 — Pullup/Pulldown configuration for GPIO 67
    values as PINCFG50.PULLCFG50
  [12] SR67 — Configure the slew rate
  [11:10] DS67 — Drive strength selection for GPIO 67
    values as PINCFG51.DS51
  [9:8] OUTCFG67 — Pin IO mode selection for GPIO pin 67
    values as PINCFG50.OUTCFG50
  [7:6] IRPTEN67 — Interrupt enable for GPIO 67
    values as PINCFG50.IRPTEN50
  [5] RDZERO67 — Return 0 for read data on GPIO 67
  [4] INPEN67 — Input enable for GPIO 67
  [3:0] FNCSEL67 — Function select for GPIO pin 67
    0=MSPI0_3 (MSPI Master 0 Interface Signal); 1=CLKOUT (Oscillator output clock); 2=SWO (Serial Wire Output); 3=GPIO (General purpose I/O); 4=UART2TX (UART transmit output (UART 2)); 5=DISP_D3 (Display Data 3); 6=CT67 (Timer/Counter input or output; Selection of direction is done via CTIMER register settings.); 7=NCE67 (IOMSTR/MSPI N Chip Select. Polarity is determined by CE_POLARITY field); 8=OBSBUS3 (Observation bus bit 3); 11=FPIO (Fast PIO)
0x110 PINCFG68 reset 0x3 — Controls the operation of GPIO pin 68.
  [27] FOEN68 — Force output enable active regardless of function selected. Otherwise the selected function will enable the output only when needed
  [26] FIEN68 — Force input enable active regardless of function selected. Otherwise the selected function will enable the input only when needed
  [22] NCEPOL68 — Polarity select for NCE for GPIO 68
    values as PINCFG50.NCEPOL50
  [21:16] NCESRC68 — IOMSTR/MSPI N Chip Select 68, DISP control signals DE, CSX, and CS. Polarity is determined by CE_POLARITY field
    values as PINCFG50.NCESRC50
  [15:13] PULLCFG68 — Pullup/Pulldown configuration for GPIO 68
    values as PINCFG50.PULLCFG50
  [12] SR68 — Configure the slew rate
  [11:10] DS68 — Drive strength selection for GPIO 68
    values as PINCFG51.DS51
  [9:8] OUTCFG68 — Pin IO mode selection for GPIO pin 68
    values as PINCFG50.OUTCFG50
  [7:6] IRPTEN68 — Interrupt enable for GPIO 68
    values as PINCFG50.IRPTEN50
  [5] RDZERO68 — Return 0 for read data on GPIO 68
  [4] INPEN68 — Input enable for GPIO 68
  [3:0] FNCSEL68 — Function select for GPIO pin 68
    0=MSPI0_4 (MSPI Master 0 Interface Signal); 1=SWO (Serial Wire Output); 3=GPIO (General purpose I/O); 4=UART0RX (UART receive input (UART 0)); 5=DISP_D4 (Display Data 4); 6=CT68 (Timer/Counter input or output; Selection of direction is done via CTIMER register settings.); 7=NCE68 (IOMSTR/MSPI N Chip Select. Polarity is determined by CE_POLARITY field); 8=OBSBUS4 (Observation bus bit 4); 11=FPIO (Fast PIO)
0x114 PINCFG69 reset 0x3 — Controls the operation of GPIO pin 69.
  [27] FOEN69 — Force output enable active regardless of function selected. Otherwise the selected function will enable the output only when needed
  [26] FIEN69 — Force input enable active regardless of function selected. Otherwise the selected function will enable the input only when needed
  [22] NCEPOL69 — Polarity select for NCE for GPIO 69
    values as PINCFG50.NCEPOL50
  [21:16] NCESRC69 — IOMSTR/MSPI N Chip Select 69, DISP control signals DE, CSX, and CS. Polarity is determined by CE_POLARITY field
    values as PINCFG50.NCESRC50
  [15:13] PULLCFG69 — Pullup/Pulldown configuration for GPIO 69
    values as PINCFG50.PULLCFG50
  [12] SR69 — Configure the slew rate
  [11:10] DS69 — Drive strength selection for GPIO 69
    values as PINCFG51.DS51
  [9:8] OUTCFG69 — Pin IO mode selection for GPIO pin 69
    values as PINCFG50.OUTCFG50
  [7:6] IRPTEN69 — Interrupt enable for GPIO 69
    values as PINCFG50.IRPTEN50
  [5] RDZERO69 — Return 0 for read data on GPIO 69
  [4] INPEN69 — Input enable for GPIO 69
  [3:0] FNCSEL69 — Function select for GPIO pin 69
    0=MSPI0_5 (MSPI Master 0 Interface Signal); 1=32KHzXT (32kHZ from analog); 2=SWO (Serial Wire Output); 3=GPIO (General purpose I/O); 4=UART2RX (UART receive input (UART 2)); 5=DISP_D5 (Display Data 5); 6=CT69 (Timer/Counter input or output; Selection of direction is done via CTIMER register settings.); 7=NCE69 (IOMSTR/MSPI N Chip Select. Polarity is determined by CE_POLARITY field); 8=OBSBUS5 (Observation bus bit 5); 11=FPIO (Fast PIO)
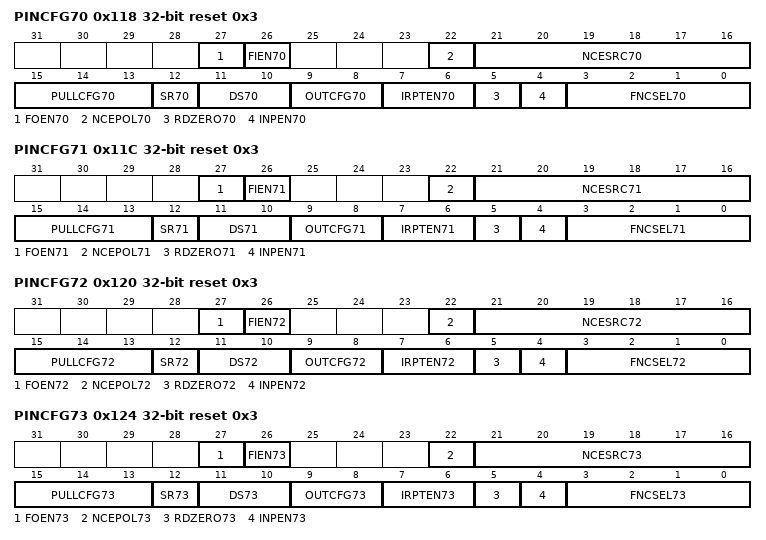
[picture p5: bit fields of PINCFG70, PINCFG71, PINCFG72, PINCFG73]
0x118 PINCFG70 reset 0x3 — Controls the operation of GPIO pin 70.
  [27] FOEN70 — Force output enable active regardless of function selected. Otherwise the selected function will enable the output only when needed
  [26] FIEN70 — Force input enable active regardless of function selected. Otherwise the selected function will enable the input only when needed
  [22] NCEPOL70 — Polarity select for NCE for GPIO 70
    values as PINCFG50.NCEPOL50
  [21:16] NCESRC70 — IOMSTR/MSPI N Chip Select 70, DISP control signals DE, CSX, and CS. Polarity is determined by CE_POLARITY field
    values as PINCFG50.NCESRC50
  [15:13] PULLCFG70 — Pullup/Pulldown configuration for GPIO 70
    values as PINCFG50.PULLCFG50
  [12] SR70 — Configure the slew rate
  [11:10] DS70 — Drive strength selection for GPIO 70
    values as PINCFG51.DS51
  [9:8] OUTCFG70 — Pin IO mode selection for GPIO pin 70
    values as PINCFG50.OUTCFG50
  [7:6] IRPTEN70 — Interrupt enable for GPIO 70
    values as PINCFG50.IRPTEN50
  [5] RDZERO70 — Return 0 for read data on GPIO 70
  [4] INPEN70 — Input enable for GPIO 70
  [3:0] FNCSEL70 — Function select for GPIO pin 70
    0=MSPI0_6 (MSPI Master 0 Interface Signal); 1=32KHzXT (32kHZ from analog); 2=SWTRACE0 (Serial Wire Debug Trace Output 0); 3=GPIO (General purpose I/O); 4=UART0RTS (UART Request to Send (RTS) (UART 0)); 5=DISP_D6 (Display Data 6); 6=CT70 (Timer/Counter input or output; Selection of direction is done via CTIMER register settings.); 7=NCE70 (IOMSTR/MSPI N Chip Select. Polarity is determined by CE_POLARITY field); 8=OBSBUS6 (Observation bus bit 6); 11=FPIO (Fast PIO)
0x11C PINCFG71 reset 0x3 — Controls the operation of GPIO pin 71.
  [27] FOEN71 — Force output enable active regardless of function selected. Otherwise the selected function will enable the output only when needed
  [26] FIEN71 — Force input enable active regardless of function selected. Otherwise the selected function will enable the input only when needed
  [22] NCEPOL71 — Polarity select for NCE for GPIO 71
    values as PINCFG50.NCEPOL50
  [21:16] NCESRC71 — IOMSTR/MSPI N Chip Select 71, DISP control signals DE, CSX, and CS. Polarity is determined by CE_POLARITY field
    values as PINCFG50.NCESRC50
  [15:13] PULLCFG71 — Pullup/Pulldown configuration for GPIO 71
    values as PINCFG50.PULLCFG50
  [12] SR71 — Configure the slew rate
  [11:10] DS71 — Drive strength selection for GPIO 71
    values as PINCFG51.DS51
  [9:8] OUTCFG71 — Pin IO mode selection for GPIO pin 71
    values as PINCFG50.OUTCFG50
  [7:6] IRPTEN71 — Interrupt enable for GPIO 71
    values as PINCFG50.IRPTEN50
  [5] RDZERO71 — Return 0 for read data on GPIO 71
  [4] INPEN71 — Input enable for GPIO 71
  [3:0] FNCSEL71 — Function select for GPIO pin 71
    0=MSPI0_7 (MSPI Master 0 Interface Signal); 1=CLKOUT (Oscillator output clock); 2=SWTRACE1 (Serial Wire Debug Trace Output 1); 3=GPIO (General purpose I/O); 4=UART0CTS (UART Clear to Send (CTS) (UART 0)); 5=DISP_D7 (Display Data 7); 6=CT71 (Timer/Counter input or output; Selection of direction is done via CTIMER register settings.); 7=NCE71 (IOMSTR/MSPI N Chip Select. Polarity is determined by CE_POLARITY field); 8=OBSBUS7 (Observation bus bit 7); 11=FPIO (Fast PIO)
0x120 PINCFG72 reset 0x3 — Controls the operation of GPIO pin 72.
  [27] FOEN72 — Force output enable active regardless of function selected. Otherwise the selected function will enable the output only when needed
  [26] FIEN72 — Force input enable active regardless of function selected. Otherwise the selected function will enable the input only when needed
  [22] NCEPOL72 — Polarity select for NCE for GPIO 72
    values as PINCFG50.NCEPOL50
  [21:16] NCESRC72 — IOMSTR/MSPI N Chip Select 72, DISP control signals DE, CSX, and CS. Polarity is determined by CE_POLARITY field
    values as PINCFG50.NCESRC50
  [15:13] PULLCFG72 — Pullup/Pulldown configuration for GPIO 72
    values as PINCFG50.PULLCFG50
  [12] SR72 — Configure the slew rate
  [11:10] DS72 — Drive strength selection for GPIO 72
    values as PINCFG51.DS51
  [9:8] OUTCFG72 — Pin IO mode selection for GPIO pin 72
    values as PINCFG50.OUTCFG50
  [7:6] IRPTEN72 — Interrupt enable for GPIO 72
    values as PINCFG50.IRPTEN50
  [5] RDZERO72 — Return 0 for read data on GPIO 72
  [4] INPEN72 — Input enable for GPIO 72
  [3:0] FNCSEL72 — Function select for GPIO pin 72
    0=MSPI0_8 (MSPI Master 0 Interface Signal); 1=CLKOUT (Oscillator output clock); 2=SWTRACE2 (Serial Wire Debug Trace Output 2); 3=GPIO (General purpose I/O); 4=UART0TX (UART transmit output (UART 0)); 5=DISP_D8 (Display Data 8); 6=CT72 (Timer/Counter input or output; Selection of direction is done via CTIMER register settings.); 7=NCE72 (IOMSTR/MSPI N Chip Select. Polarity is determined by CE_POLARITY field); 8=OBSBUS8 (Observation bus bit 8); 9=VCMPO (Output of the voltage comparator signal); 11=FPIO (Fast PIO)
0x124 PINCFG73 reset 0x3 — Controls the operation of GPIO pin 73.
  [27] FOEN73 — Force output enable active regardless of function selected. Otherwise the selected function will enable the output only when needed
  [26] FIEN73 — Force input enable active regardless of function selected. Otherwise the selected function will enable the input only when needed
  [22] NCEPOL73 — Polarity select for NCE for GPIO 73
    values as PINCFG50.NCEPOL50
  [21:16] NCESRC73 — IOMSTR/MSPI N Chip Select 73, DISP control signals DE, CSX, and CS. Polarity is determined by CE_POLARITY field
    values as PINCFG50.NCESRC50
  [15:13] PULLCFG73 — Pullup/Pulldown configuration for GPIO 73
    values as PINCFG50.PULLCFG50
  [12] SR73 — Configure the slew rate
  [11:10] DS73 — Drive strength selection for GPIO 73
    values as PINCFG51.DS51
  [9:8] OUTCFG73 — Pin IO mode selection for GPIO pin 73
    values as PINCFG50.OUTCFG50
  [7:6] IRPTEN73 — Interrupt enable for GPIO 73
    values as PINCFG50.IRPTEN50
  [5] RDZERO73 — Return 0 for read data on GPIO 73
  [4] INPEN73 — Input enable for GPIO 73
  [3:0] FNCSEL73 — Function select for GPIO pin 73
    0=MSPI0_9 (MSPI Master 0 Interface Signal); 2=SWTRACE3 (Serial Wire Debug Trace Output 3); 3=GPIO (General purpose I/O); 4=UART2TX (UART transmit output (UART 2)); 5=DISP_D9 (Display Data 9); 6=CT73 (Timer/Counter input or output; Selection of direction is done via CTIMER register settings.); 7=NCE73 (IOMSTR/MSPI N Chip Select. Polarity is determined by CE_POLARITY field); 8=OBSBUS9 (Observation bus bit 9); 11=FPIO (Fast PIO)
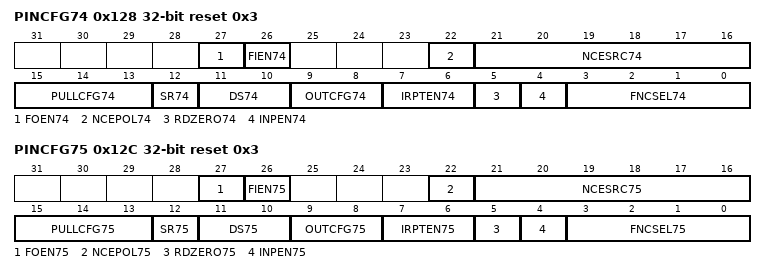
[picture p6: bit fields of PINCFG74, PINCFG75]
0x128 PINCFG74 reset 0x3 — Controls the operation of GPIO pin 74.
  [27] FOEN74 — Force output enable active regardless of function selected. Otherwise the selected function will enable the output only when needed
  [26] FIEN74 — Force input enable active regardless of function selected. Otherwise the selected function will enable the input only when needed
  [22] NCEPOL74 — Polarity select for NCE for GPIO 74
    values as PINCFG50.NCEPOL50
  [21:16] NCESRC74 — IOMSTR/MSPI N Chip Select 74, DISP control signals DE, CSX, and CS. Polarity is determined by CE_POLARITY field
    values as PINCFG50.NCESRC50
  [15:13] PULLCFG74 — Pullup/Pulldown configuration for GPIO 74
    values as PINCFG50.PULLCFG50
  [12] SR74 — Configure the slew rate
  [11:10] DS74 — Drive strength selection for GPIO 74
    values as PINCFG51.DS51
  [9:8] OUTCFG74 — Pin IO mode selection for GPIO pin 74
    values as PINCFG50.OUTCFG50
  [7:6] IRPTEN74 — Interrupt enable for GPIO 74
    values as PINCFG50.IRPTEN50
  [5] RDZERO74 — Return 0 for read data on GPIO 74
  [4] INPEN74 — Input enable for GPIO 74
  [3:0] FNCSEL74 — Function select for GPIO pin 74
    0=MSPI2_0 (MSPI Master 2 Interface Signal); 1=DISP_QSPI_D0_OUT (Display SPI Data0); 2=DISP_QSPI_D0 (Display SPI Data0); 3=GPIO (General purpose I/O); 4=UART0RX (UART receive input (UART 0)); 5=DISP_D10 (Display Data 10); 6=CT74 (Timer/Counter input or output; Selection of direction is done via CTIMER register settings.); 7=NCE74 (IOMSTR/MSPI N Chip Select. Polarity is determined by CE_POLARITY field); 8=OBSBUS10 (Observation bus bit 10); 9=DISP_SPI_SD (Display SPI Data Out); 10=DISP_SPI_SDO (Display SPI Data Out); 11=FPIO (Fast PIO)
0x12C PINCFG75 reset 0x3 — Controls the operation of GPIO pin 75.
  [27] FOEN75 — Force output enable active regardless of function selected. Otherwise the selected function will enable the output only when needed
  [26] FIEN75 — Force input enable active regardless of function selected. Otherwise the selected function will enable the input only when needed
  [22] NCEPOL75 — Polarity select for NCE for GPIO 75
    values as PINCFG50.NCEPOL50
  [21:16] NCESRC75 — IOMSTR/MSPI N Chip Select 75, DISP control signals DE, CSX, and CS. Polarity is determined by CE_POLARITY field
    values as PINCFG50.NCESRC50
  [15:13] PULLCFG75 — Pullup/Pulldown configuration for GPIO 75
    values as PINCFG50.PULLCFG50
  [12] SR75 — Configure the slew rate
  [11:10] DS75 — Drive strength selection for GPIO 75
    values as PINCFG51.DS51
  [9:8] OUTCFG75 — Pin IO mode selection for GPIO pin 75
    values as PINCFG50.OUTCFG50
  [7:6] IRPTEN75 — Interrupt enable for GPIO 75
    values as PINCFG50.IRPTEN50
  [5] RDZERO75 — Return 0 for read data on GPIO 75
  [4] INPEN75 — Input enable for GPIO 75
  [3:0] FNCSEL75 — Function select for GPIO pin 75
    0=MSPI2_1 (MSPI Master 2 Interface Signal); 1=32KHzXT (32kHZ from analog); 2=DISP_QSPI_D1 (Display SPI Data1); 3=GPIO (General purpose I/O); 4=UART2RX (UART receive input (UART 2)); 5=DISP_D11 (Display Data 11); 6=CT75 (Timer/Counter input or output; Selection of direction is done via CTIMER register settings.); 7=NCE75 (IOMSTR/MSPI N Chip Select. Polarity is determined by CE_POLARITY field); 8=OBSBUS11 (Observation bus bit 11); 9=DISP_SPI_DCX (Display SPI DCx); 11=FPIO (Fast PIO)
